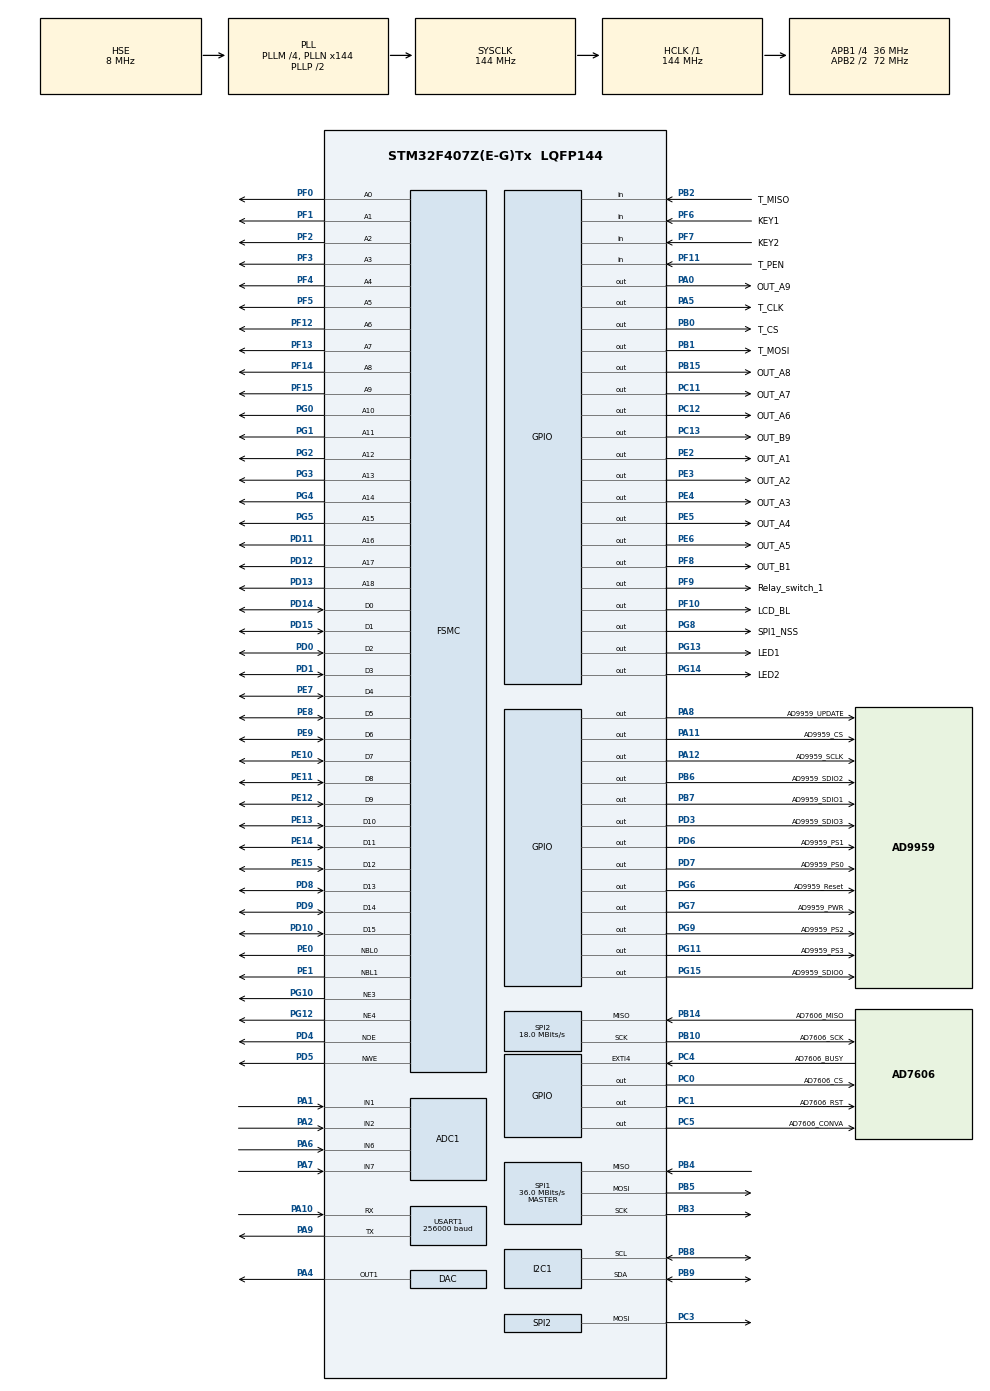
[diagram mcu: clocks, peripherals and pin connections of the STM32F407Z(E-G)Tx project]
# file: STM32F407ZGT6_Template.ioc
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ADC1.Channel-2\#ChannelRegularConversion=ADC_CHANNEL_1
ADC1.Channel-5\#ChannelRegularConversion=ADC_CHANNEL_2
ADC1.Channel-6\#ChannelRegularConversion=ADC_CHANNEL_6
ADC1.Channel-7\#ChannelRegularConversion=ADC_CHANNEL_7
ADC1.ClockPrescaler=ADC_CLOCK_SYNC_PCLK_DIV4
ADC1.DMAContinuousRequests=ENABLE
ADC1.EOCSelection=ADC_EOC_SEQ_CONV
ADC1.ExternalTrigConv=ADC_EXTERNALTRIGCONV_T3_TRGO
ADC1.ExternalTrigConvEdge=ADC_EXTERNALTRIGCONVEDGE_RISINGFALLING
ADC1.InjNumberOfConversion=0
ADC1.NbrOfConversion=4
ADC1.NbrOfConversionFlag=1
ADC1.Rank-2\#ChannelRegularConversion=1
ADC1.Rank-5\#ChannelRegularConversion=2
ADC1.Rank-6\#ChannelRegularConversion=3
ADC1.Rank-7\#ChannelRegularConversion=4
ADC1.SamplingTime-2\#ChannelRegularConversion=ADC_SAMPLETIME_3CYCLES
ADC1.SamplingTime-5\#ChannelRegularConversion=ADC_SAMPLETIME_3CYCLES
ADC1.SamplingTime-6\#ChannelRegularConversion=ADC_SAMPLETIME_3CYCLES
ADC1.SamplingTime-7\#ChannelRegularConversion=ADC_SAMPLETIME_3CYCLES
ADC1.ScanConvMode=ENABLE
ADC1.master=1
DAC.DAC_OutputBuffer=DAC_OUTPUTBUFFER_DISABLE
DAC.DAC_Trigger=DAC_TRIGGER_SOFTWARE
Dma.ADC1.0.Direction=DMA_PERIPH_TO_MEMORY
Dma.ADC1.0.FIFOMode=DMA_FIFOMODE_DISABLE
Dma.ADC1.0.Instance=DMA2_Stream4
Dma.ADC1.0.MemDataAlignment=DMA_MDATAALIGN_HALFWORD
Dma.ADC1.0.MemInc=DMA_MINC_ENABLE
Dma.ADC1.0.Mode=DMA_NORMAL
Dma.ADC1.0.PeriphDataAlignment=DMA_PDATAALIGN_HALFWORD
Dma.ADC1.0.PeriphInc=DMA_PINC_DISABLE
Dma.ADC1.0.Priority=DMA_PRIORITY_MEDIUM
Dma.Request0=ADC1
FSMC.AddressSetupTime1=15
FSMC.AddressSetupTime2=3
FSMC.BusTurnAroundDuration1=0
FSMC.BusTurnAroundDuration2=3
FSMC.DataSetupTime1=60
FSMC.DataSetupTime2=7
FSMC.ExtendedAddressSetupTime1=9
FSMC.ExtendedBusTurnAroundDuration1=0
FSMC.ExtendedDataSetupTime1=8
FSMC.ExtendedMode1=FSMC_EXTENDED_MODE_ENABLE
FSMC.WriteOperation2=FSMC_WRITE_OPERATION_ENABLE
Mcu.Family=STM32F4
Mcu.Name=STM32F407Z(E-G)Tx
Mcu.Package=LQFP144
NVIC.ADC_IRQn=true\:3\:0\:true\:false\:true\:true\:true\:true
NVIC.DMA2_Stream4_IRQn=true\:3\:0\:true\:false\:true\:false\:true\:true
NVIC.EXTI4_IRQn=true\:3\:0\:true\:false\:true\:true\:true\:true
NVIC.PriorityGroup=NVIC_PRIORITYGROUP_4
NVIC.TIM6_DAC_IRQn=true\:3\:0\:true\:false\:true\:true\:true\:true
NVIC.TIM7_IRQn=true\:15\:0\:true\:false\:true\:true\:true\:true
NVIC.USART1_IRQn=true\:8\:0\:true\:false\:true\:true\:true\:true
PA0-WKUP.GPIO_Label=OUT_A9
PA0-WKUP.Signal=GPIO_Output
PA1.Signal=ADCx_IN1
PA10.Mode=Asynchronous
PA10.Signal=USART1_RX
PA11.GPIO_Label=AD9959_CS
PA11.GPIO_PuPd=GPIO_PULLUP
PA11.GPIO_Speed=GPIO_SPEED_FREQ_HIGH
PA11.Signal=GPIO_Output
PA12.GPIO_Label=AD9959_SCLK
PA12.GPIO_PuPd=GPIO_PULLUP
PA12.GPIO_Speed=GPIO_SPEED_FREQ_HIGH
PA12.Signal=GPIO_Output
PA13.Mode=Serial_Wire
PA13.Signal=SYS_JTMS-SWDIO
PA14.Mode=Serial_Wire
PA14.Signal=SYS_JTCK-SWCLK
PA2.Signal=ADCx_IN2
PA4.Signal=COMP_DAC1_group
PA5.GPIO_Label=T_CLK
PA5.GPIO_Speed=GPIO_SPEED_FREQ_HIGH
PA5.Signal=GPIO_Output
PA6.Signal=ADCx_IN6
PA7.Signal=ADCx_IN7
PA8.GPIO_Label=AD9959_UPDATE
PA8.GPIO_PuPd=GPIO_PULLUP
PA8.GPIO_Speed=GPIO_SPEED_FREQ_HIGH
PA8.Signal=GPIO_Output
PA9.Mode=Asynchronous
PA9.Signal=USART1_TX
PB0.GPIO_Label=T_CS
PB0.GPIO_Speed=GPIO_SPEED_FREQ_HIGH
PB0.Signal=GPIO_Output
PB1.GPIO_Label=T_MOSI
PB1.GPIO_Speed=GPIO_SPEED_FREQ_HIGH
PB1.Signal=GPIO_Output
PB10.GPIO_Label=AD7606_SCK
PB10.Mode=Full_Duplex_Master
PB10.Signal=SPI2_SCK
PB14.GPIO_Label=AD7606_MISO
PB14.Mode=Full_Duplex_Master
PB14.Signal=SPI2_MISO
PB15.GPIO_Label=OUT_A8
PB15.Signal=GPIO_Output
PB2.GPIO_Label=T_MISO
PB2.GPIO_Mode=GPIO_MODE_INPUT
PB2.Signal=GPIO_Input
PB3.Mode=Full_Duplex_Master
PB3.Signal=SPI1_SCK
PB4.Mode=Full_Duplex_Master
PB4.Signal=SPI1_MISO
PB5.Mode=Full_Duplex_Master
PB5.Signal=SPI1_MOSI
PB6.GPIO_Label=AD9959_SDIO2
PB6.GPIO_PuPd=GPIO_PULLUP
PB6.GPIO_Speed=GPIO_SPEED_FREQ_HIGH
PB6.Signal=GPIO_Output
PB7.GPIO_Label=AD9959_SDIO1
PB7.GPIO_PuPd=GPIO_PULLUP
PB7.GPIO_Speed=GPIO_SPEED_FREQ_HIGH
PB7.Signal=GPIO_Output
PB8.Mode=I2C
PB8.Signal=I2C1_SCL
PB9.Mode=I2C
PB9.Signal=I2C1_SDA
PC0.GPIO_Label=AD7606_CS
PC0.Signal=GPIO_Output
PC1.GPIO_Label=AD7606_RST
PC1.Signal=GPIO_Output
PC11.GPIO_Label=OUT_A7
PC11.Signal=GPIO_Output
PC12.GPIO_Label=OUT_A6
PC12.Signal=GPIO_Output
PC13-ANTI_TAMP.GPIO_Label=OUT_B9
PC13-ANTI_TAMP.Signal=GPIO_Output
PC14-OSC32_IN.Mode=LSE-External-Oscillator
PC14-OSC32_IN.Signal=RCC_OSC32_IN
PC15-OSC32_OUT.Mode=LSE-External-Oscillator
PC15-OSC32_OUT.Signal=RCC_OSC32_OUT
PC3.Mode=Full_Duplex_Master
PC3.Signal=SPI2_MOSI
PC4.GPIO_Label=AD7606_BUSY
PC4.GPIO_ModeDefaultEXTI=GPIO_MODE_IT_FALLING
PC4.Signal=GPXTI4
PC5.GPIO_Label=AD7606_CONVA
PC5.Signal=GPIO_Output
PD0.Signal=FSMC_D2_DA2
PD1.Signal=FSMC_D3_DA3
PD10.Signal=FSMC_D15_DA15
PD11.Signal=FSMC_A16_CLE
PD12.Signal=FSMC_A17_ALE
PD13.Signal=FSMC_A18
PD14.Signal=FSMC_D0_DA0
PD15.Signal=FSMC_D1_DA1
PD3.GPIO_Label=AD9959_SDIO3
PD3.GPIO_PuPd=GPIO_PULLUP
PD3.GPIO_Speed=GPIO_SPEED_FREQ_HIGH
PD3.Signal=GPIO_Output
PD4.Signal=FSMC_NOE
PD5.Signal=FSMC_NWE
PD6.GPIO_Label=AD9959_PS1
PD6.GPIO_PuPd=GPIO_PULLUP
PD6.GPIO_Speed=GPIO_SPEED_FREQ_HIGH
PD6.Signal=GPIO_Output
PD7.GPIO_Label=AD9959_PS0
PD7.GPIO_PuPd=GPIO_PULLUP
PD7.GPIO_Speed=GPIO_SPEED_FREQ_HIGH
PD7.Signal=GPIO_Output
PD8.Signal=FSMC_D13_DA13
PD9.Signal=FSMC_D14_DA14
PE0.Signal=FSMC_NBL0
PE1.Signal=FSMC_NBL1
PE10.Signal=FSMC_D7_DA7
PE11.Signal=FSMC_D8_DA8
PE12.Signal=FSMC_D9_DA9
PE13.Signal=FSMC_D10_DA10
PE14.Signal=FSMC_D11_DA11
PE15.Signal=FSMC_D12_DA12
PE2.GPIO_Label=OUT_A1
PE2.Signal=GPIO_Output
PE3.GPIO_Label=OUT_A2
PE3.Signal=GPIO_Output
PE4.GPIO_Label=OUT_A3
PE4.Signal=GPIO_Output
PE5.GPIO_Label=OUT_A4
PE5.Signal=GPIO_Output
PE6.GPIO_Label=OUT_A5
PE6.Signal=GPIO_Output
PE7.Signal=FSMC_D4_DA4
PE8.Signal=FSMC_D5_DA5
PE9.Signal=FSMC_D6_DA6
PF0.Signal=FSMC_A0
PF1.Signal=FSMC_A1
PF10.GPIO_Label=LCD_BL
PF10.GPIO_Speed=GPIO_SPEED_FREQ_HIGH
PF10.Signal=GPIO_Output
PF11.GPIO_Label=T_PEN
PF11.Signal=GPIO_Input
PF12.Signal=FSMC_A6
PF13.Signal=FSMC_A7
PF14.Signal=FSMC_A8
PF15.Signal=FSMC_A9
PF2.Signal=FSMC_A2
PF3.Signal=FSMC_A3
PF4.Signal=FSMC_A4
PF5.Signal=FSMC_A5
PF6.GPIO_Label=KEY1
PF6.GPIO_Mode=GPIO_MODE_INPUT
PF6.GPIO_PuPd=GPIO_PULLUP
PF6.Signal=GPIO_Input
PF7.GPIO_Label=KEY2
PF7.GPIO_Mode=GPIO_MODE_INPUT
PF7.GPIO_PuPd=GPIO_PULLUP
PF7.Signal=GPIO_Input
PF8.GPIO_Label=OUT_B1
PF8.Signal=GPIO_Output
PF9.GPIO_Label=Relay_switch_1
PF9.Signal=GPIO_Output
PG0.Signal=FSMC_A10
PG1.Signal=FSMC_A11
PG10.Mode=NorPsramChipSelect3_2
PG10.Signal=FSMC_NE3
PG11.GPIO_Label=AD9959_PS3
PG11.GPIO_PuPd=GPIO_PULLUP
PG11.GPIO_Speed=GPIO_SPEED_FREQ_HIGH
PG11.Signal=GPIO_Output
PG12.Mode=NorPsramChipSelect4_1
PG12.Signal=FSMC_NE4
PG13.GPIO_Label=LED1
PG13.GPIO_Speed=GPIO_SPEED_FREQ_HIGH
PG13.PinState=GPIO_PIN_SET
PG13.Signal=GPIO_Output
PG14.GPIO_Label=LED2
PG14.GPIO_Speed=GPIO_SPEED_FREQ_HIGH
PG14.PinState=GPIO_PIN_SET
PG14.Signal=GPIO_Output
PG15.GPIO_Label=AD9959_SDIO0
PG15.GPIO_PuPd=GPIO_PULLUP
PG15.GPIO_Speed=GPIO_SPEED_FREQ_HIGH
PG15.Signal=GPIO_Output
PG2.Signal=FSMC_A12
PG3.Signal=FSMC_A13
PG4.Signal=FSMC_A14
PG5.Signal=FSMC_A15
PG6.GPIO_Label=AD9959_Reset
PG6.GPIO_PuPd=GPIO_PULLUP
PG6.GPIO_Speed=GPIO_SPEED_FREQ_HIGH
PG6.Signal=GPIO_Output
PG7.GPIO_Label=AD9959_PWR
PG7.GPIO_PuPd=GPIO_PULLUP
PG7.GPIO_Speed=GPIO_SPEED_FREQ_HIGH
PG7.Signal=GPIO_Output
PG8.GPIO_Label=SPI1_NSS
PG8.GPIO_Speed=GPIO_SPEED_FREQ_HIGH
PG8.PinState=GPIO_PIN_SET
PG8.Signal=GPIO_Output
PG9.GPIO_Label=AD9959_PS2
PG9.GPIO_PuPd=GPIO_PULLUP
PG9.GPIO_Speed=GPIO_SPEED_FREQ_HIGH
PG9.Signal=GPIO_Output
PH0-OSC_IN.Mode=HSE-External-Oscillator
PH0-OSC_IN.Signal=RCC_OSC_IN
PH1-OSC_OUT.Mode=HSE-External-Oscillator
PH1-OSC_OUT.Signal=RCC_OSC_OUT
ProjectManager.HeapSize=0x200
ProjectManager.StackSize=0x400
ProjectManager.TargetToolchain=MDK-ARM V5
RCC.48MHZClocksFreq_Value=72000000
RCC.AHBFreq_Value=144000000
RCC.APB1CLKDivider=RCC_HCLK_DIV4
RCC.APB1Freq_Value=36000000
RCC.APB1TimFreq_Value=72000000
RCC.APB2CLKDivider=RCC_HCLK_DIV2
RCC.APB2Freq_Value=72000000
RCC.APB2TimFreq_Value=144000000
RCC.CortexFreq_Value=144000000
RCC.HCLKFreq_Value=144000000
RCC.HSE_VALUE=8000000
RCC.HSI_VALUE=16000000
RCC.PLLM=4
RCC.PLLN=144
RCC.PLLSourceVirtual=RCC_PLLSOURCE_HSE
RCC.SYSCLKFreq_VALUE=144000000
RCC.SYSCLKSource=RCC_SYSCLKSOURCE_PLLCLK
RCC.VCOOutputFreq_Value=288000000
SH.ADCx_IN1.0=ADC1_IN1,IN1
SH.ADCx_IN2.0=ADC1_IN2,IN2
SH.ADCx_IN6.0=ADC1_IN6,IN6
SH.ADCx_IN7.0=ADC1_IN7,IN7
SH.COMP_DAC1_group.0=DAC_OUT1,DAC_OUT1
SH.FSMC_A0.0=FSMC_A0,19b-a2
SH.FSMC_A1.0=FSMC_A1,19b-a2
SH.FSMC_A10.0=FSMC_A10,19b-a2
SH.FSMC_A11.0=FSMC_A11,19b-a2
SH.FSMC_A12.0=FSMC_A12,A12_1
SH.FSMC_A12.1=FSMC_A12,19b-a2
SH.FSMC_A13.0=FSMC_A13,19b-a2
SH.FSMC_A14.0=FSMC_A14,19b-a2
SH.FSMC_A15.0=FSMC_A15,19b-a2
SH.FSMC_A16_CLE.0=FSMC_A16,19b-a2
SH.FSMC_A17_ALE.0=FSMC_A17,19b-a2
SH.FSMC_A18.0=FSMC_A18,19b-a2
SH.FSMC_A2.0=FSMC_A2,19b-a2
SH.FSMC_A3.0=FSMC_A3,19b-a2
SH.FSMC_A4.0=FSMC_A4,19b-a2
SH.FSMC_A5.0=FSMC_A5,19b-a2
SH.FSMC_A6.0=FSMC_A6,19b-a2
SH.FSMC_A7.0=FSMC_A7,19b-a2
SH.FSMC_A8.0=FSMC_A8,19b-a2
SH.FSMC_A9.0=FSMC_A9,19b-a2
SH.FSMC_D0_DA0.0=FSMC_D0,16b-d1
SH.FSMC_D0_DA0.1=FSMC_D0,16b-d2
SH.FSMC_D10_DA10.0=FSMC_D10,16b-d1
SH.FSMC_D10_DA10.1=FSMC_D10,16b-d2
SH.FSMC_D11_DA11.0=FSMC_D11,16b-d1
SH.FSMC_D11_DA11.1=FSMC_D11,16b-d2
SH.FSMC_D12_DA12.0=FSMC_D12,16b-d1
SH.FSMC_D12_DA12.1=FSMC_D12,16b-d2
SH.FSMC_D13_DA13.0=FSMC_D13,16b-d1
SH.FSMC_D13_DA13.1=FSMC_D13,16b-d2
SH.FSMC_D14_DA14.0=FSMC_D14,16b-d1
SH.FSMC_D14_DA14.1=FSMC_D14,16b-d2
SH.FSMC_D15_DA15.0=FSMC_D15,16b-d1
SH.FSMC_D15_DA15.1=FSMC_D15,16b-d2
SH.FSMC_D1_DA1.0=FSMC_D1,16b-d1
SH.FSMC_D1_DA1.1=FSMC_D1,16b-d2
SH.FSMC_D2_DA2.0=FSMC_D2,16b-d1
SH.FSMC_D2_DA2.1=FSMC_D2,16b-d2
SH.FSMC_D3_DA3.0=FSMC_D3,16b-d1
SH.FSMC_D3_DA3.1=FSMC_D3,16b-d2
SH.FSMC_D4_DA4.0=FSMC_D4,16b-d1
SH.FSMC_D4_DA4.1=FSMC_D4,16b-d2
SH.FSMC_D5_DA5.0=FSMC_D5,16b-d1
SH.FSMC_D5_DA5.1=FSMC_D5,16b-d2
SH.FSMC_D6_DA6.0=FSMC_D6,16b-d1
SH.FSMC_D6_DA6.1=FSMC_D6,16b-d2
SH.FSMC_D7_DA7.0=FSMC_D7,16b-d1
SH.FSMC_D7_DA7.1=FSMC_D7,16b-d2
SH.FSMC_D8_DA8.0=FSMC_D8,16b-d1
SH.FSMC_D8_DA8.1=FSMC_D8,16b-d2
SH.FSMC_D9_DA9.0=FSMC_D9,16b-d1
SH.FSMC_D9_DA9.1=FSMC_D9,16b-d2
SH.FSMC_NBL0.0=FSMC_NBL0,2ByteEnable2
SH.FSMC_NBL1.0=FSMC_NBL1,2ByteEnable2
SH.FSMC_NOE.0=FSMC_NOE,Lcd1
SH.FSMC_NOE.1=FSMC_NOE,Sram2
SH.FSMC_NWE.0=FSMC_NWE,Lcd1
SH.FSMC_NWE.1=FSMC_NWE,Sram2
SPI1.CalculateBaudRate=36.0 MBits/s
SPI1.Direction=SPI_DIRECTION_2LINES
SPI1.Mode=SPI_MODE_MASTER
SPI1.VirtualType=VM_MASTER
SPI2.CalculateBaudRate=18.0 MBits/s
SPI2.DataSize=SPI_DATASIZE_16BIT
SPI2.Direction=SPI_DIRECTION_2LINES
SPI2.Mode=SPI_MODE_MASTER
SPI2.VirtualType=VM_MASTER
TIM3.AutoReloadPreload=TIM_AUTORELOAD_PRELOAD_ENABLE
TIM3.Period=90-1
TIM3.Prescaler=4-1
TIM3.TIM_MasterOutputTrigger=TIM_TRGO_UPDATE
TIM6.AutoReloadPreload=TIM_AUTORELOAD_PRELOAD_ENABLE
TIM6.Period=72-1
TIM6.Prescaler=0
TIM6.TIM_MasterOutputTrigger=TIM_TRGO_UPDATE
TIM7.AutoReloadPreload=TIM_AUTORELOAD_PRELOAD_ENABLE
TIM7.Period=1000-1
TIM7.Prescaler=72-1
USART1.BaudRate=256000
USART1.VirtualMode=VM_ASYNC
VP_TIM3_VS_ClockSourceINT.Mode=Internal
VP_TIM6_VS_ClockSourceINT.Mode=Enable_Timer
VP_TIM7_VS_ClockSourceINT.Mode=Enable_Timer
board=custom

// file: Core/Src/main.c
/* USER CODE BEGIN Header */
/**
  ******************************************************************************
  * @file           : main.c
  * @brief          : Main program body
  ******************************************************************************
  * @attention
  *
  * Copyright (c) 2023 STMicroelectronics.
  * All rights reserved.
  *
  * This software is licensed under terms that can be found in the LICENSE file
  * in the root directory of this software component.
  * If no LICENSE file comes with this software, it is provided AS-IS.
  *
  ******************************************************************************
  */
/* USER CODE END Header */
#include "main.h"
#include "adc.h"
#include "dac.h"
#include "dma.h"
#include "i2c.h"
#include "spi.h"
#include "tim.h"
#include "usart.h"
#include "gpio.h"
#include "fsmc.h"

/* USER CODE BEGIN Includes */

#include "Function.h"

/* USER CODE END Includes */

void SystemClock_Config(void);

int main(void)
{

  /* MCU Configuration--------------------------------------------------------*/

  /* Reset of all peripherals, Initializes the Flash interface and the Systick. */
  HAL_Init();

  /* Configure the system clock */
  SystemClock_Config();

  /* Initialize all configured peripherals */
  MX_GPIO_Init();
  MX_DMA_Init();
  MX_I2C1_Init();
  MX_SPI1_Init();
  MX_TIM7_Init();
  MX_FSMC_Init();
  MX_TIM6_Init();
  MX_ADC1_Init();
  MX_USART1_UART_Init();
  MX_SPI2_Init();
  MX_TIM3_Init();
  MX_DAC_Init();
  /* USER CODE BEGIN 2 */
	UserSystemInit();

  /* USER CODE END 2 */

  /* Infinite loop */
  /* USER CODE BEGIN WHILE */
  while (1)
  {
		IWDG_Feed();

		Task_Touch();

		Task_KEY();

		Task_LED();

		Task_Msg();

		Task_UART1();

		function_Task();

		Time_count();
//		AD9959_FixedStepSweep_10bit();

    /* USER CODE END WHILE */

  }
}

void SystemClock_Config(void)
{
  RCC_OscInitTypeDef RCC_OscInitStruct = {0};
  RCC_ClkInitTypeDef RCC_ClkInitStruct = {0};

  /** Configure the main internal regulator output voltage
  */
  __HAL_RCC_PWR_CLK_ENABLE();
  __HAL_PWR_VOLTAGESCALING_CONFIG(PWR_REGULATOR_VOLTAGE_SCALE1);

  /** Initializes the RCC Oscillators according to the specified parameters
  * in the RCC_OscInitTypeDef structure.
  */
  RCC_OscInitStruct.OscillatorType = RCC_OSCILLATORTYPE_HSE;
  RCC_OscInitStruct.HSEState = RCC_HSE_ON;
  RCC_OscInitStruct.PLL.PLLState = RCC_PLL_ON;
  RCC_OscInitStruct.PLL.PLLSource = RCC_PLLSOURCE_HSE;
  RCC_OscInitStruct.PLL.PLLM = 4;
  RCC_OscInitStruct.PLL.PLLN = 144;
  RCC_OscInitStruct.PLL.PLLP = RCC_PLLP_DIV2;
  RCC_OscInitStruct.PLL.PLLQ = 4;
  if (HAL_RCC_OscConfig(&RCC_OscInitStruct) != HAL_OK)
  {
    Error_Handler();
  }

  /** Initializes the CPU, AHB and APB buses clocks
  */
  RCC_ClkInitStruct.ClockType = RCC_CLOCKTYPE_HCLK|RCC_CLOCKTYPE_SYSCLK
                              |RCC_CLOCKTYPE_PCLK1|RCC_CLOCKTYPE_PCLK2;
  RCC_ClkInitStruct.SYSCLKSource = RCC_SYSCLKSOURCE_PLLCLK;
  RCC_ClkInitStruct.AHBCLKDivider = RCC_SYSCLK_DIV1;
  RCC_ClkInitStruct.APB1CLKDivider = RCC_HCLK_DIV4;
  RCC_ClkInitStruct.APB2CLKDivider = RCC_HCLK_DIV2;

  if (HAL_RCC_ClockConfig(&RCC_ClkInitStruct, FLASH_LATENCY_4) != HAL_OK)
  {
    Error_Handler();
  }
}

void Error_Handler(void)
{
  __disable_irq();
  while (1)
  {
  }
}
